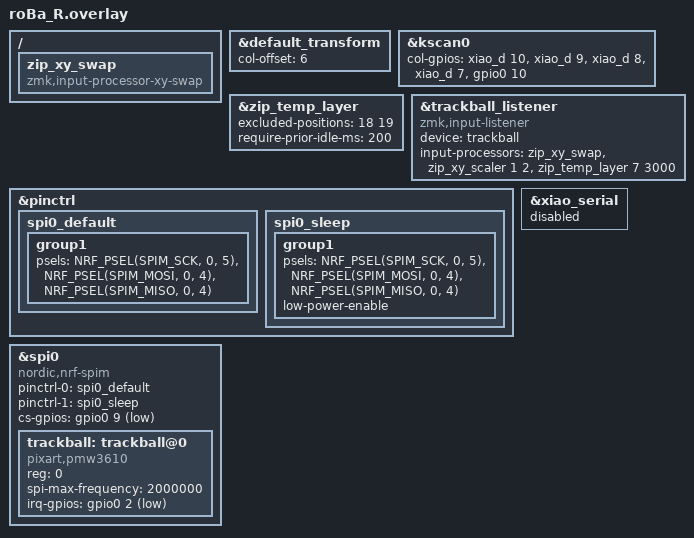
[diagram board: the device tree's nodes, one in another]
#include "roBa.dtsi"
#include <input/processors.dtsi>

&default_transform {
    col-offset = <6>;
};

&kscan0 {
    col-gpios
        = <&xiao_d 10 GPIO_ACTIVE_HIGH>
        , <&xiao_d 9 GPIO_ACTIVE_HIGH>
        , <&xiao_d 8 GPIO_ACTIVE_HIGH>
        , <&xiao_d 7 GPIO_ACTIVE_HIGH>
        , <&gpio0 10 GPIO_ACTIVE_HIGH>
        ;
};

/* 1. 軸を入れ替えるための「道具（ノード）」を定義 */
/ {
    zip_xy_swap: zip_xy_swap {
        compatible = "zmk,input-processor-xy-swap";
        #input-processor-cells = <0>;
    };
};

/* 2. オートレイヤー（AML）の挙動詳細設定 */
&zip_temp_layer {
    /* マウス操作中に押しても解除されないキー（18:T, 19:N） */
    excluded-positions = <18 19>; 
    /* 打鍵直後の誤爆防止（200ms） */
    require-prior-idle-ms = <200>; 
};

/* 3. トラックボールの挙動を一括管理（ここが重要） */
&trackball_listener {
    status = "okay";
    compatible = "zmk,input-listener";
    device = <&trackball>;

    /* 実行順序が重要です：
       ①軸を入れ替える → ②感度を2倍にする → ③レイヤー7を3秒間起動する 
    */
    input-processors = 
        <&zip_xy_swap>, 
        <&zip_xy_scaler 1 2>, 
        <&zip_temp_layer 7 3000>;
};

&pinctrl {
    spi0_default: spi0_default {
        group1 {
            psels = <NRF_PSEL(SPIM_SCK, 0, 5)>,
                <NRF_PSEL(SPIM_MOSI, 0, 4)>,
                <NRF_PSEL(SPIM_MISO, 0, 4)>;
        };
    };

    spi0_sleep: spi0_sleep {
        group1 {
            psels = <NRF_PSEL(SPIM_SCK, 0, 5)>,
                <NRF_PSEL(SPIM_MOSI, 0, 4)>,
                <NRF_PSEL(SPIM_MISO, 0, 4)>;
            low-power-enable;
        };
    };
};

&xiao_serial { status = "disabled"; };

#include <zephyr/dt-bindings/input/input-event-codes.h>

&spi0 {
    status = "okay";
    compatible = "nordic,nrf-spim";
    pinctrl-0 = <&spi0_default>;
    pinctrl-1 = <&spi0_sleep>;
    pinctrl-names = "default", "sleep";
    cs-gpios = <&gpio0 9 GPIO_ACTIVE_LOW>;

    trackball: trackball@0 {
        status = "okay";
        compatible = "pixart,pmw3610";
        reg = <0>;
        spi-max-frequency = <2000000>;
        irq-gpios = <&gpio0 2 (GPIO_ACTIVE_LOW | GPIO_PULL_UP)>;
    };
};
